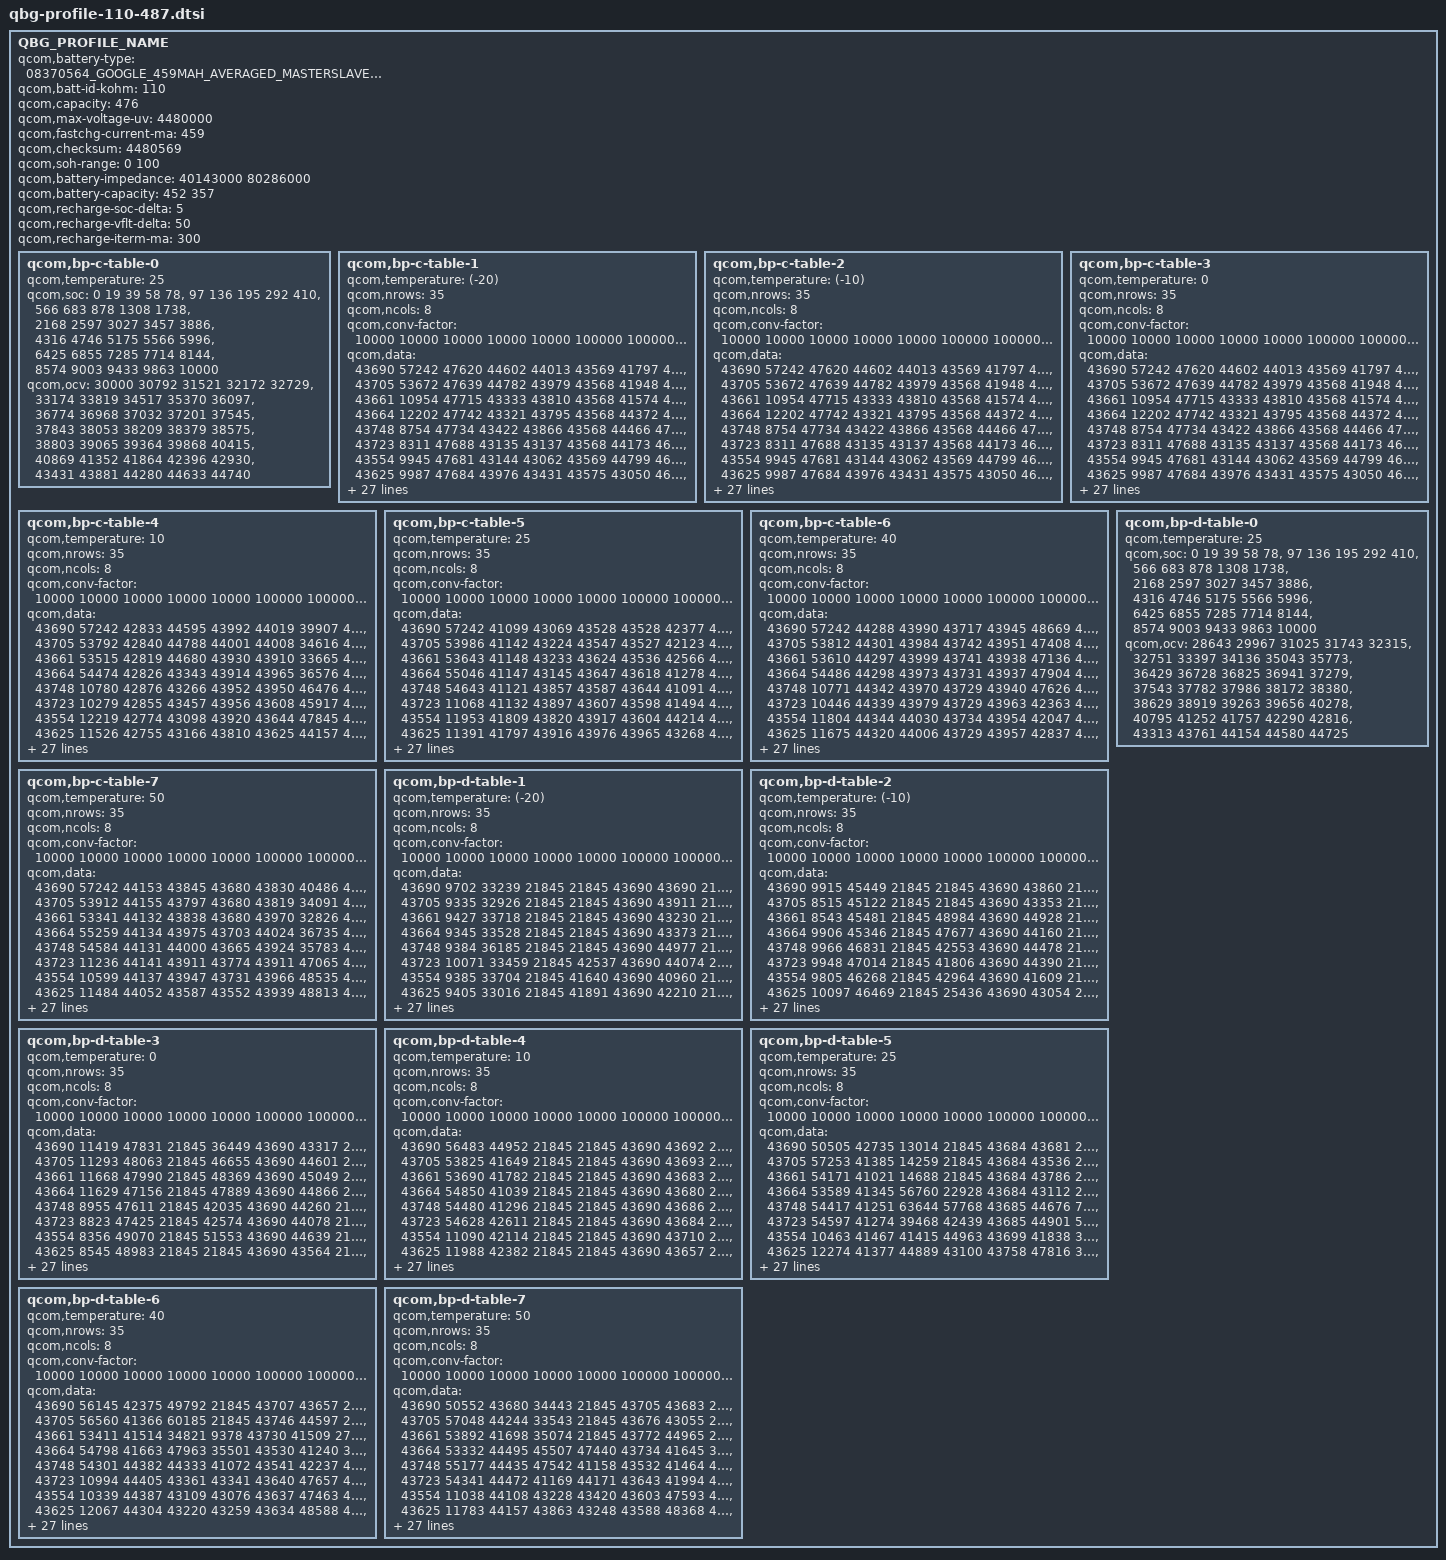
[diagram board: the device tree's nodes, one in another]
/*QBG Profiling Rev. 2.8*/

QBG_PROFILE_NAME {
	qcom,battery-type = "08370564_GOOGLE_459MAH_AVERAGED_MASTERSLAVE_MAR4TH2026";
	qcom,batt-id-kohm = <110>;
	qcom,capacity = <476>;
	qcom,max-voltage-uv = <4480000>;
	qcom,fastchg-current-ma = <459>;
	qcom,checksum = <4480569>; /*@5, 0.005V, 4% */
	qcom,soh-range = <0 100>;
	qcom,battery-impedance = <40143000 80286000>; /*Nominal_Impedance in 10nohm @ SOC 50% 25C* 0:fresh cell, 1: aged cell*/
	qcom,battery-capacity = <452 357>; /*Nominal_Capacity in mAh. 0: fresh cell, 1:aged cell*/ 
	qcom,recharge-soc-delta =<5>; /*SOC delta (in percent) dropped from EOC SOC to enable recharge*/ 
	qcom,recharge-vflt-delta =<50>; /*vfloat delta (in mV) dropped from regular vfloat in recharge*/ 
	qcom,recharge-iterm-ma = <300>; /*termination current (in mA) in recharge*/ 

	qcom,bp-c-table-0 {
		qcom,temperature = <25>;
		qcom,soc = <    0    19    39    58    78>,
			<   97   136   195   292   410>,
			<  566   683   878  1308  1738>,
			< 2168  2597  3027  3457  3886>,
			< 4316  4746  5175  5566  5996>,
			< 6425  6855  7285  7714  8144>,
			< 8574  9003  9433  9863 10000>;
		qcom,ocv = <30000 30792 31521 32172 32729>,
			<33174 33819 34517 35370 36097>,
			<36774 36968 37032 37201 37545>,
			<37843 38053 38209 38379 38575>,
			<38803 39065 39364 39868 40415>,
			<40869 41352 41864 42396 42930>,
			<43431 43881 44280 44633 44740>;
	};
	qcom,bp-c-table-1 {
		qcom,temperature = <(-20)>;
		qcom,nrows = <35>;
		qcom,ncols = <8>;
		qcom,conv-factor = <10000 10000 10000 10000 10000 100000 100000 10000>;
		qcom,data = <43690 57242 47620 44602 44013 43569 41797 46970>,
			<43705 53672 47639 44782 43979 43568 41948 46856>,
			<43661 10954 47715 43333 43810 43568 41574 47070>,
			<43664 12202 47742 43321 43795 43568 44372 47085>,
			<43748  8754 47734 43422 43866 43568 44466 47024>,
			<43723  8311 47688 43135 43137 43568 44173 46661>,
			<43554  9945 47681 43144 43062 43569 44799 46645>,
			<43625  9987 47684 43976 43431 43575 43050 46743>,
			<43918  9670 47718 43602 43405 43534 43862 45436>,
			<43824 15100 47735 43734 43307 43531 43808 45351>,
			<43164 14854 47725 43529 43495 43532 43798 45564>,
			<43009 14967 47725 43533 43515 43526 43874 45561>,
			<43460 15249 47712 43638 43416 43538 43171 45512>,
			<44982 14381 48039 43977 44565 43522 43837 47076>,
			<44128 14594 48124 44874 43104 43551 48741 46437>,
			<41682 16087 48055 41688 43985 43537 46532 35346>,
			<41103 16293 47706 41919 43891 43538 47010 35817>,
			<41337 16162 47703 41928 43188 43550 45266 35661>,
			<42795 15537 48024 41747 43255 43525 45688 34924>,
			<42372 15481 48094 41098 43047 43520 45980 35075>,
			<47734 15724 47920 41173 43068 43534 46002 36601>,
			<47136 13219 47890 41066 43058 43572 48266 36431>,
			<48797 12327 47940 41031 43025 43580 42095 36635>,
			<48916 12637 47331 41372 43403 43557 41074 35904>,
			<48582 14129 47148 41435 43371 43565 44391 33477>,
			<46003 13820 47218 41238 44753 43562 44174 32916>,
			<45165  2957 47596 42656 45054 43734 44930 34549>,
			<46815  2468 47377 42728 44226 43731 44764 33906>,
			<46216  4015 48774 42709 44408 43731 43353 39782>,
			<46458  3501 48653 42512 41748 43734 43299 40715>,
			<35796   607 49057 42884 42717 43732 43503 36901>,
			<35201    17 49098 42583 48104 43733 43083 60256>,
			<36467  1735 48998 41174 48128 43521 43173 60443>,
			<35885  1857 48190 44844 45613 43647 43967 60762>,
			<36282  1260 48524 44644 48539 43768 43585 58042>;
	};
	qcom,bp-c-table-2 {
		qcom,temperature = <(-10)>;
		qcom,nrows = <35>;
		qcom,ncols = <8>;
		qcom,conv-factor = <10000 10000 10000 10000 10000 100000 100000 10000>;
		qcom,data = <43690 57242 47620 44602 44013 43569 41797 46970>,
			<43705 53672 47639 44782 43979 43568 41948 46856>,
			<43661 10954 47715 43333 43810 43568 41574 47070>,
			<43664 12202 47742 43321 43795 43568 44372 47085>,
			<43748  8754 47734 43422 43866 43568 44466 47024>,
			<43723  8311 47688 43135 43137 43568 44173 46661>,
			<43554  9945 47681 43144 43062 43569 44799 46645>,
			<43625  9987 47684 43976 43431 43575 43050 46743>,
			<43918  9670 47718 43602 43405 43534 43862 45436>,
			<43824 15100 47735 43734 43307 43531 43808 45351>,
			<43164 14854 47725 43529 43495 43532 43798 45564>,
			<43009 14967 47725 43533 43515 43526 43874 45561>,
			<43460 15249 47712 43638 43416 43538 43171 45512>,
			<44982 14381 48039 43977 44565 43522 43837 47076>,
			<44128 14594 48124 44874 43104 43551 48741 46437>,
			<41682 16087 48055 41688 43985 43537 46532 35346>,
			<41103 16293 47706 41919 43891 43538 47010 35817>,
			<41337 16162 47703 41928 43188 43550 45266 35661>,
			<42795 15537 48024 41747 43255 43525 45688 34924>,
			<42372 15481 48094 41098 43047 43520 45980 35075>,
			<47734 15724 47920 41173 43068 43534 46002 36601>,
			<47136 13219 47890 41066 43058 43572 48266 36431>,
			<48797 12327 47940 41031 43025 43580 42095 36635>,
			<48916 12637 47331 41372 43403 43557 41074 35904>,
			<48582 14129 47148 41435 43371 43565 44391 33477>,
			<46003 13820 47218 41238 44753 43562 44174 32916>,
			<45165  2957 47596 42656 45054 43734 44930 34549>,
			<46815  2468 47377 42728 44226 43731 44764 33906>,
			<46216  4015 48774 42709 44408 43731 43353 39782>,
			<46458  3501 48653 42512 41748 43734 43299 40715>,
			<35796   607 49057 42884 42717 43732 43503 36901>,
			<35201    17 49098 42583 48104 43733 43083 60256>,
			<36467  1735 48998 41174 48128 43521 43173 60443>,
			<35885  1857 48190 44844 45613 43647 43967 60762>,
			<36282  1260 48524 44644 48539 43768 43585 58042>;
	};
	qcom,bp-c-table-3 {
		qcom,temperature = <0>;
		qcom,nrows = <35>;
		qcom,ncols = <8>;
		qcom,conv-factor = <10000 10000 10000 10000 10000 100000 100000 10000>;
		qcom,data = <43690 57242 47620 44602 44013 43569 41797 46970>,
			<43705 53672 47639 44782 43979 43568 41948 46856>,
			<43661 10954 47715 43333 43810 43568 41574 47070>,
			<43664 12202 47742 43321 43795 43568 44372 47085>,
			<43748  8754 47734 43422 43866 43568 44466 47024>,
			<43723  8311 47688 43135 43137 43568 44173 46661>,
			<43554  9945 47681 43144 43062 43569 44799 46645>,
			<43625  9987 47684 43976 43431 43575 43050 46743>,
			<43918  9670 47718 43602 43405 43534 43862 45436>,
			<43824 15100 47735 43734 43307 43531 43808 45351>,
			<43164 14854 47725 43529 43495 43532 43798 45564>,
			<43009 14967 47725 43533 43515 43526 43874 45561>,
			<43460 15249 47712 43638 43416 43538 43171 45512>,
			<44982 14381 48039 43977 44565 43522 43837 47076>,
			<44128 14594 48124 44874 43104 43551 48741 46437>,
			<41682 16087 48055 41688 43985 43537 46532 35346>,
			<41103 16293 47706 41919 43891 43538 47010 35817>,
			<41337 16162 47703 41928 43188 43550 45266 35661>,
			<42795 15537 48024 41747 43255 43525 45688 34924>,
			<42372 15481 48094 41098 43047 43520 45980 35075>,
			<47734 15724 47920 41173 43068 43534 46002 36601>,
			<47136 13219 47890 41066 43058 43572 48266 36431>,
			<48797 12327 47940 41031 43025 43580 42095 36635>,
			<48916 12637 47331 41372 43403 43557 41074 35904>,
			<48582 14129 47148 41435 43371 43565 44391 33477>,
			<46003 13820 47218 41238 44753 43562 44174 32916>,
			<45165  2957 47596 42656 45054 43734 44930 34549>,
			<46815  2468 47377 42728 44226 43731 44764 33906>,
			<46216  4015 48774 42709 44408 43731 43353 39782>,
			<46458  3501 48653 42512 41748 43734 43299 40715>,
			<35796   607 49057 42884 42717 43732 43503 36901>,
			<35201    17 49098 42583 48104 43733 43083 60256>,
			<36467  1735 48998 41174 48128 43521 43173 60443>,
			<35885  1857 48190 44844 45613 43647 43967 60762>,
			<36282  1260 48524 44644 48539 43768 43585 58042>;
	};
	qcom,bp-c-table-4 {
		qcom,temperature = <10>;
		qcom,nrows = <35>;
		qcom,ncols = <8>;
		qcom,conv-factor = <10000 10000 10000 10000 10000 100000 100000 10000>;
		qcom,data = <43690 57242 42833 44595 43992 44019 39907 45741>,
			<43705 53792 42840 44788 44001 44008 34616 48415>,
			<43661 53515 42819 44680 43930 43910 33665 48586>,
			<43664 54474 42826 43343 43914 43965 36576 48544>,
			<43748 10780 42876 43266 43952 43950 46476 48156>,
			<43723 10279 42855 43457 43956 43608 45917 48329>,
			<43554 12219 42774 43098 43920 43644 47845 48998>,
			<43625 11526 42755 43166 43810 43625 44157 49035>,
			<43918  8256 42800 43588 43216 43636 43165 48676>,
			<43824  9987 42803 43624 43221 43602 43173 48775>,
			<43164 15026 42961 43722 43020 43958 43784 47469>,
			<43009 14907 42787 43721 43008 43956 43826 47370>,
			<43460 14969 42957 43531 43207 43955 43179 47397>,
			<44982 15112 42947 44697 43647 43595 45463 49103>,
			<44128 14431 42986 44933 43948 43616 35571 48261>,
			<41682 16038 42916 44812 43910 43631 46547 48373>,
			<41103 15994 42568 44913 44003 43625 45349 48320>,
			<41337 16370 42604 44864 43975 43624 45782 48345>,
			<42795 16197 42526 44889 43835 43624 48263 48173>,
			<42372 15369 42520 44216 43776 43624 48404 48135>,
			<47734 15657 42544 44185 43781 43624 46619 48226>,
			<47136 12833 42551 44045 43803 43541 32906 48609>,
			<48797 12444 42523 44050 43828 43549 46396 48625>,
			<48916 12633 42592 44136 43788 43527 48101 48426>,
			<48582 14102 42562 44114 43860 43534 41454 45806>,
			<46003 13612 42937 44521 43206 43569 41506 46063>,
			<45165  3023 42983 44314 43135 43576 44530 45266>,
			<46815  2550 42808 41603 43491 43559 44131 45435>,
			<46216  4033 42865 41671 43356 43553 44888 47099>,
			<46458  3537 42115 41497 44633 43553 45054 46483>,
			<35796   986 42200 41500 44069 43556 44558 35589>,
			<35201   413 42001 41504 41939 43582 43331 36823>,
			<36467  1662 42424 44289 42780 43581 43431 33626>,
			<35885  1173 42253 44651 42108 43565 43880 32963>,
			<36282  1085 47774 43338 42701 43737 44018 33408>;
	};
	qcom,bp-c-table-5 {
		qcom,temperature = <25>;
		qcom,nrows = <35>;
		qcom,ncols = <8>;
		qcom,conv-factor = <10000 10000 10000 10000 10000 100000 100000 10000>;
		qcom,data = <43690 57242 41099 43069 43528 43528 42377 42066>,
			<43705 53986 41142 43224 43547 43527 42123 42098>,
			<43661 53643 41148 43233 43624 43536 42566 42013>,
			<43664 55046 41147 43145 43647 43618 41278 42045>,
			<43748 54643 41121 43857 43587 43644 41091 42194>,
			<43723 11068 41132 43897 43607 43598 41494 42224>,
			<43554 11953 41809 43820 43917 43604 44214 42121>,
			<43625 11391 41797 43916 43976 43965 43268 42827>,
			<43918  8320 41803 43527 43796 43918 43051 42800>,
			<43824 10155 41848 43565 43898 43945 43166 42954>,
			<43164  9484 41748 43920 43600 43935 44872 42889>,
			<43009 15042 41755 43646 44026 43912 43518 42583>,
			<43460 14850 41755 43535 43813 43909 43078 42583>,
			<44982 15355 41781 43106 43646 43592 48774 42178>,
			<44128 14339 41768 43411 43939 43641 48748 42054>,
			<41682 14713 41975 43475 43960 43623 48975 42414>,
			<41103 15887 41877 43320 43960 43622 48354 42411>,
			<41337 16363 41859 43300 43904 43623 47534 42077>,
			<42795 16193 41915 43475 43977 43621 42837 42410>,
			<42372 15365 41903 43457 43788 43621 41301 42369>,
			<47734 15673 41565 43310 43885 43617 42161 42480>,
			<47136 12851 41541 43370 43886 43622 48672 42298>,
			<48797 13166 41540 44680 43830 43644 33956 42261>,
			<48916 12566 41539 43375 43978 43643 46015 42368>,
			<48582 14197 41550 43299 44017 43616 41855 42060>,
			<46003 13583 41550 43289 43808 43624 41620 42478>,
			<45165  2850 41541 44727 43891 43544 44145 47804>,
			<46815  2338 41897 44765 43163 43520 44223 47692>,
			<46216  3894 41870 44663 43218 43532 44186 47978>,
			<46458  3352 41979 44970 43454 43532 45012 47111>,
			<35796   781 41947 44975 43332 43526 44624 47465>,
			<35201   451 41780 44630 45037 43549 44596 49143>,
			<36467  1618 41849 44576 41715 43627 43360 45795>,
			<35885  1267 41186 43400 41486 43527 43104 45731>,
			<36282  1134 41050 43173 44499 43626 43821 48141>;
	};
	qcom,bp-c-table-6 {
		qcom,temperature = <40>;
		qcom,nrows = <35>;
		qcom,ncols = <8>;
		qcom,conv-factor = <10000 10000 10000 10000 10000 100000 100000 10000>;
		qcom,data = <43690 57242 44288 43990 43717 43945 48669 41104>,
			<43705 53812 44301 43984 43742 43951 47408 41118>,
			<43661 53610 44297 43999 43741 43938 47136 41095>,
			<43664 54486 44298 43973 43731 43937 47904 41103>,
			<43748 10771 44342 43970 43729 43940 47626 41142>,
			<43723 10446 44339 43979 43729 43963 42363 41145>,
			<43554 11804 44344 44030 43734 43954 42047 41131>,
			<43625 11675 44320 44006 43729 43957 42837 41799>,
			<43918  8441 44331 44000 43741 43907 42004 41842>,
			<43824 10145 44509 43918 43579 43927 41116 41748>,
			<43164  9533 44506 43592 43548 43980 44427 41786>,
			<43009 15094 44483 43962 43727 44011 47226 41926>,
			<43460 14904 44494 43960 43728 44009 47813 41943>,
			<44982 15259 44534 43815 43604 43938 41357 40993>,
			<44128 14382 44516 43880 43952 43604 41298 41078>,
			<41682 14592 44437 43847 43938 43615 47903 41033>,
			<41103 15919 44421 43867 43602 43611 47142 41060>,
			<41337 16272 44426 43844 43607 43608 42003 41071>,
			<42795 16208 44472 43895 43926 43612 41127 41036>,
			<42372 15458 44460 43815 43903 43601 44196 41356>,
			<47734 15623 44117 43801 43866 43590 41658 41417>,
			<47136 12819 44113 43858 43890 43596 42715 41253>,
			<48797 13144 44125 43210 43834 43605 46686 41216>,
			<48916 12632 44127 43860 44012 43608 42146 41387>,
			<48582 14163 44121 43884 44001 43586 44275 41081>,
			<46003 13678 44126 43877 43999 43595 44949 41389>,
			<45165  2822 44114 43865 43788 43644 44593 41412>,
			<46815  2331 44116 43164 43894 43618 44745 41296>,
			<46216  3950 44462 43106 43184 43536 44563 42570>,
			<46458  3454 44478 43092 43217 43539 44561 42793>,
			<35796   789 44429 43507 43130 43621 44861 42217>,
			<35201   466 44522 43468 43320 43598 44814 42374>,
			<36467  1962 44483 43436 45018 43589 44583 47618>,
			<35885  1271 44311 43144 44842 43638 43330 47765>,
			<36282  1150 41511 43875 44998 43963 43165 47669>;
	};
	qcom,bp-c-table-7 {
		qcom,temperature = <50>;
		qcom,nrows = <35>;
		qcom,ncols = <8>;
		qcom,conv-factor = <10000 10000 10000 10000 10000 100000 100000 10000>;
		qcom,data = <43690 57242 44153 43845 43680 43830 40486 41548>,
			<43705 53912 44155 43797 43680 43819 34091 41545>,
			<43661 53341 44132 43838 43680 43970 32826 41589>,
			<43664 55259 44134 43975 43703 44024 36735 41584>,
			<43748 54584 44131 44000 43665 43924 35783 41599>,
			<43723 11236 44141 43911 43774 43911 47065 41594>,
			<43554 10599 44137 43947 43731 43966 48535 41583>,
			<43625 11484 44052 43587 43552 43939 48813 41494>,
			<43918  8978 44050 43958 43773 43930 45649 41502>,
			<43824  9763 44059 43609 43740 44000 42794 41524>,
			<43164  9604 44033 43628 43581 43984 44405 41513>,
			<43009 14987 44034 43524 43718 43817 42971 41623>,
			<43460 15095 44047 43641 43712 43971 47247 41674>,
			<44982 14938 44043 43914 43603 43922 41954 41952>,
			<44128 14562 44082 44011 43960 43910 41740 41763>,
			<41682 14787 44069 44021 43942 43913 42394 41784>,
			<41103 16127 44078 44017 43600 43957 42276 41949>,
			<41337 16270 44242 44021 43586 43953 42956 41928>,
			<42795 16199 44228 44020 43940 43956 40971 41762>,
			<42372 15465 44239 43612 43884 43920 44560 41826>,
			<47734 15620 44234 43960 43848 43953 44244 41815>,
			<47136 12907 44278 44020 43798 43940 41348 41098>,
			<48797 12462 44272 43804 43986 43941 45976 41114>,
			<48916 13996 44275 43970 43967 43960 41290 41771>,
			<48582 14165 44274 43931 43956 43961 44802 41930>,
			<46003 13669 44274 43926 44015 43936 44654 41765>,
			<45165  2834 44273 43998 44019 43615 44670 41817>,
			<46815  2410 44277 43882 43989 43636 44646 41181>,
			<46216  3965 44233 43190 43883 43621 44569 41358>,
			<46458  3403 44225 43051 43843 43622 44902 41322>,
			<35796   865 44243 43071 43212 43633 44827 42748>,
			<35201   297 44076 43069 43431 43614 44846 42924>,
			<36467  1962 44043 43207 44772 43966 44950 42120>,
			<35885  1225 44145 43988 44688 43606 43388 43000>,
			<36282  1136 44308 43884 43382 43930 43454 42174>;
	};
	qcom,bp-d-table-0 {
		qcom,temperature = <25>;
		qcom,soc = <    0    19    39    58    78>,
			<   97   136   195   292   410>,
			<  566   683   878  1308  1738>,
			< 2168  2597  3027  3457  3886>,
			< 4316  4746  5175  5566  5996>,
			< 6425  6855  7285  7714  8144>,
			< 8574  9003  9433  9863 10000>;
		qcom,ocv = <28643 29967 31025 31743 32315>,
			<32751 33397 34136 35043 35773>,
			<36429 36728 36825 36941 37279>,
			<37543 37782 37986 38172 38380>,
			<38629 38919 39263 39656 40278>,
			<40795 41252 41757 42290 42816>,
			<43313 43761 44154 44580 44725>;
	};
	qcom,bp-d-table-1 {
		qcom,temperature = <(-20)>;
		qcom,nrows = <35>;
		qcom,ncols = <8>;
		qcom,conv-factor = <10000 10000 10000 10000 10000 100000 100000 10000>;
		qcom,data = <43690  9702 33239 21845 21845 43690 43690 21845>,
			<43705  9335 32926 21845 21845 43690 43911 21845>,
			<43661  9427 33718 21845 21845 43690 43230 21845>,
			<43664  9345 33528 21845 21845 43690 43373 21845>,
			<43748  9384 36185 21845 21845 43690 44977 21845>,
			<43723 10071 33459 21845 42537 43690 44074 21845>,
			<43554  9385 33704 21845 41640 43690 40960 21845>,
			<43625  9405 33016 21845 41891 43690 42210 21845>,
			<43918  9294 33277 21845 18957 43690 43736 21845>,
			<43824  9607 32872 21845 56997 43690 43535 21845>,
			<43164  9513 32805 21845 60280 43690 43618 21845>,
			<43009  9568 33597 21845 34815 43690 43936 21845>,
			<43460 15001 36159 21845 36554 43690 43825 21845>,
			<44982 15272 36471 15036 45174 43691 43023 21845>,
			<44128 15108 35039 65214 47377 43688 43471 23503>,
			<41682 14584 35774 36921 41986 43689 44782  4417>,
			<41103 14425 46353 33035 41414 43694 44643 12313>,
			<41337 14640 46197 35054 41777 43695 44627 12182>,
			<42795 16121 46284 46784 41685 43692 44991 56442>,
			<42372 16305 46886 45606 44327 43693 44998 50830>,
			<47734 16208 46917 48290 44140 43683 44200 53135>,
			<47136 15445 47068 49083 44180 43680 44126 51416>,
			<48797 13029 47061 48754 44179 43680 41492 52186>,
			<48916 13079 46886 48649 44229 43681 41097 52118>,
			<48582 12757 47042 48867 44430 43686 41036 52206>,
			<46003 14299 46886 48878 44376 43687 41438 51973>,
			<45165 13790 46212 48698 41593 43684 41400 51224>,
			<46815  2849 46908 48680 41950 43707 41352 51677>,
			<46216  2368 47040 48819 41926 43750 42053 53181>,
			<46458  3224 47090 48827 41948 43740 48069 52340>,
			<35796   694 47034 48710 41748 43719 42395 52537>,
			<35201   886 46661 48930 41931 43722 41427 52515>,
			<36467   284 47036 48403 41619 43700 44366 52299>,
			<35885  1884 46890 45073 44047 43690 44779 53014>,
			<36282  1134 46852 45346 44182 43690 43452 53244>;
	};
	qcom,bp-d-table-2 {
		qcom,temperature = <(-10)>;
		qcom,nrows = <35>;
		qcom,ncols = <8>;
		qcom,conv-factor = <10000 10000 10000 10000 10000 100000 100000 10000>;
		qcom,data = <43690  9915 45449 21845 21845 43690 43860 21845>,
			<43705  8515 45122 21845 21845 43690 43353 21845>,
			<43661  8543 45481 21845 48984 43690 44928 21845>,
			<43664  9906 45346 21845 47677 43690 44160 21845>,
			<43748  9966 46831 21845 42553 43690 44478 21845>,
			<43723  9948 47014 21845 41806 43690 44390 21845>,
			<43554  9805 46268 21845 42964 43690 41609 21845>,
			<43625 10097 46469 21845 25436 43690 43054 21845>,
			<43918  9218 46582 21845  7142 43690 43565 21845>,
			<43824  9653 46158 21845 60053 43690 43585 21845>,
			<43164  9521 46319 21845 45365 43690 43998 21845>,
			<43009  9554 46659 16741 47917 43690 43138 21845>,
			<43460 15058 46754 63012 41010 43691 43488 21165>,
			<44982 15252 45591 35863 41892 43689 44667  9586>,
			<44128 15220 48549 48466 44225 43695 44883 52393>,
			<41682 14547 48232 47109 44850 43693 44223 64612>,
			<41103 14783 48205 42363 45040 43680 44804 64130>,
			<41337 14614 48564 42848 44979 43687 44835 57809>,
			<42795 16081 48572 42621 44785 43707 44438 58109>,
			<42372 16324 48521 42647 44710 43699 41741 60453>,
			<47734 15369 48532 41353 43372 43716 47799 61205>,
			<47136 15702 48622 41378 44713 43552 48024 61205>,
			<48797 13274 48616 41455 44589 43556 47649 61284>,
			<48916 12364 48532 41271 44609 43578 42254 61305>,
			<48582 13853 48540 42650 45004 43579 42446 60594>,
			<46003 13342 46010 42568 44888 43556 42049 60487>,
			<45165  2659 48605 42774 44227 43554 42016 60751>,
			<46815  2117 48531 41994 44148 43563 42238 58294>,
			<46216  4027 48528 42494 44515 43731 42774 57506>,
			<46458  3507 48515 42308 44350 43736 42544 57417>,
			<35796   606 48545 47658 44292 43713 41463 57727>,
			<35201    60 48518 47715 44513 43721 41785 59061>,
			<36467  1677 48207 47676 44814 43772 41472 57756>,
			<35885  1203 48353 42334 43492 43756 41497 58157>,
			<36282  1124 48314 42252 43115 43755 41900 58277>;
	};
	qcom,bp-d-table-3 {
		qcom,temperature = <0>;
		qcom,nrows = <35>;
		qcom,ncols = <8>;
		qcom,conv-factor = <10000 10000 10000 10000 10000 100000 100000 10000>;
		qcom,data = <43690 11419 47831 21845 36449 43690 43317 21845>,
			<43705 11293 48063 21845 46655 43690 44601 21845>,
			<43661 11668 47990 21845 48369 43690 45049 21845>,
			<43664 11629 47156 21845 47889 43690 44866 21845>,
			<43748  8955 47611 21845 42035 43690 44260 21845>,
			<43723  8823 47425 21845 42574 43690 44078 21845>,
			<43554  8356 49070 21845 51553 43690 44639 21845>,
			<43625  8545 48983 21845 21845 43690 43564 21845>,
			<43918 10199 48184 21845 13531 43690 43717 21845>,
			<43824  9265 49013 21845 34140 43690 43604 21845>,
			<43164  9711 48727 19819 42024 43690 43141 21845>,
			<43009  9535 48698 51378 44294 43691 43518 16696>,
			<43460 15033 47368 46766 44968 43688 44753 54653>,
			<44982 14942 47345 42996 43323 43693 44469 57356>,
			<44128 15123 47259 41765 43078 43658 41002 36878>,
			<41682 14385 47266 41632 43050 43555 48921 40485>,
			<41103 14845 47353 44305 43061 43580 48134 39846>,
			<41337 14677 47349 44507 43060 43569 47188 33794>,
			<42795 15990 47322 44486 43107 43530 47537 34595>,
			<42372 16229 47320 44533 43436 43528 47695 34403>,
			<47734 15434 47350 44482 43423 43535 41994 34559>,
			<47136 12979 47304 44348 43511 43532 42969 34486>,
			<48797 13098 47147 44406 43322 43534 42496 34469>,
			<48916 12381 47345 41618 43364 43531 42736 34542>,
			<48582 13926 47333 41496 44724 43575 42642 34315>,
			<46003 13437 47305 41983 44756 43570 42536 34599>,
			<45165  2644 47333 41818 44661 43576 42688 33828>,
			<46815  2433 47353 41159 44957 43558 41321 34059>,
			<46216  4064 47358 40991 45012 43567 41166 39623>,
			<46458  3556 47256 41084 44848 43733 41893 39499>,
			<35796   902 47240 41030 44845 43728 41684 39815>,
			<35201   115 47295 41384 44965 43730 41497 39918>,
			<36467  1776 47245 41022 44735 43737 41551 39542>,
			<35885  1167 47355 41841 43036 43719 41917 39558>,
			<36282  1123 47307 41759 43234 43713 41869 39596>;
	};
	qcom,bp-d-table-4 {
		qcom,temperature = <10>;
		qcom,nrows = <35>;
		qcom,ncols = <8>;
		qcom,conv-factor = <10000 10000 10000 10000 10000 100000 100000 10000>;
		qcom,data = <43690 56483 44952 21845 21845 43690 43692 21845>,
			<43705 53825 41649 21845 21845 43690 43693 21845>,
			<43661 53690 41782 21845 21845 43690 43683 21845>,
			<43664 54850 41039 21845 21845 43690 43680 21845>,
			<43748 54480 41296 21845 21845 43690 43686 21845>,
			<43723 54628 42611 21845 21845 43690 43684 21845>,
			<43554 11090 42114 21845 21845 43690 43710 21845>,
			<43625 11988 42382 21845 21845 43690 43657 21845>,
			<43918 11597 47771 21845 21845 43690 43762 21845>,
			<43824  8274 47803 21845 34111 43690 43605 21845>,
			<43164  9387 42461 53331 41884 43691 43518 22374>,
			<43009  9654 42429 33186 44627 43691 44821 15343>,
			<43460  9481 42047 41718 43119 43683 44325 38832>,
			<44982 15084 42003 44763 43821 43716 41197 34845>,
			<44128 15152 42211 45013 43188 43575 49123 35419>,
			<41682 14395 42122 45029 43011 43527 47273 46293>,
			<41103 14840 42144 45025 43008 43548 47345 47027>,
			<41337 16033 42838 45032 43020 43536 47961 46739>,
			<42795 15996 42837 44959 43010 43537 47789 45362>,
			<42372 16147 42158 44954 43022 43537 42877 45489>,
			<47734 15383 42832 44950 43066 43536 42527 45152>,
			<47136 15681 42123 45041 43053 43538 42703 45060>,
			<48797 13293 42155 44997 43061 43551 41408 45074>,
			<48916 12305 42144 44855 43113 43550 41278 45149>,
			<48582 13873 42158 44888 43438 43544 42643 45358>,
			<46003 13434 42155 44089 43463 43545 42433 46650>,
			<45165  3006 42834 44456 43385 43547 42310 46909>,
			<46815  2460 42842 44455 44735 43533 42671 46210>,
			<46216  4064 42839 44112 44672 43530 41910 46114>,
			<46458  3574 42137 44469 44707 43575 41514 46511>,
			<35796  1005 42153 44435 43387 43568 41482 46377>,
			<35201    84 42168 44421 43319 43570 41881 46460>,
			<36467  1750 42120 44110 43446 43583 41939 46436>,
			<35885  1159 42140 44238 43211 43579 41973 46390>,
			<36282  1134 42131 44266 43143 43578 41899 46548>;
	};
	qcom,bp-d-table-5 {
		qcom,temperature = <25>;
		qcom,nrows = <35>;
		qcom,ncols = <8>;
		qcom,conv-factor = <10000 10000 10000 10000 10000 100000 100000 10000>;
		qcom,data = <43690 50505 42735 13014 21845 43684 43681 21845>,
			<43705 57253 41385 14259 21845 43684 43536 21845>,
			<43661 54171 41021 14688 21845 43684 43786 21845>,
			<43664 53589 41345 56760 22928 43684 43112 21845>,
			<43748 54417 41251 63644 57768 43685 44676  7543>,
			<43723 54597 41274 39468 42439 43685 44901 52134>,
			<43554 10463 41467 41415 44963 43699 41838 37871>,
			<43625 12274 41377 44889 43100 43758 47816 34923>,
			<43918  8777 41063 44799 43227 43578 45794 45823>,
			<43824  8471 40960 43335 43141 43524 46282 49072>,
			<43164  9447 41187 43393 43990 43524 41378 47946>,
			<43009  9682 41116 43515 43825 43619 41070 47873>,
			<43460  9587 41103 43072 43909 43540 41290 47867>,
			<44982 15079 41817 43207 43640 43620 42386 42061>,
			<44128 15157 41753 43121 43789 43642 42690 42259>,
			<41682 14349 41765 43085 43186 43639 42713 42310>,
			<41103 14652 41775 43454 43218 43590 42415 47864>,
			<41337 16072 41942 43402 43066 43589 42376 47857>,
			<42795 16310 41922 43094 43054 43586 41323 47787>,
			<42372 16198 41981 43074 43240 43595 41089 42277>,
			<47734 15439 41953 43076 43871 43637 41109 42386>,
			<47136 12973 41966 43091 43798 43639 41026 42068>,
			<48797 13301 41877 43094 43806 43632 41395 42072>,
			<48916 12354 41875 43411 43855 43636 42160 42481>,
			<48582 14332 41862 43385 43415 43586 48608 48123>,
			<46003 13809 41869 43378 43307 43595 47587 47920>,
			<45165  2958 41869 43324 43495 43643 40997 48000>,
			<46815  2487 41859 43311 43436 43620 41715 47728>,
			<46216  3992 41883 43289 43040 43646 41672 47631>,
			<46458  3562 41966 43384 43198 43646 41915 47834>,
			<35796   923 41976 43337 43807 43643 41399 47849>,
			<35201    91 41924 43291 43787 43621 41265 47750>,
			<36467  1744 41761 43474 43785 43642 41275 47770>,
			<35885  1166 41741 43421 43803 43647 41346 47852>,
			<36282  1055 41754 43402 43794 43634 41049 47867>;
	};
	qcom,bp-d-table-6 {
		qcom,temperature = <40>;
		qcom,nrows = <35>;
		qcom,ncols = <8>;
		qcom,conv-factor = <10000 10000 10000 10000 10000 100000 100000 10000>;
		qcom,data = <43690 56145 42375 49792 21845 43707 43657 21845>,
			<43705 56560 41366 60185 21845 43746 44597 21845>,
			<43661 53411 41514 34821  9378 43730 41509 27151>,
			<43664 54798 41663 47963 35501 43530 41240 38116>,
			<43748 54301 44382 44333 41072 43541 42237 46630>,
			<43723 10994 44405 43361 43341 43640 47657 47709>,
			<43554 10339 44387 43109 43076 43637 47463 42037>,
			<43625 12067 44304 43220 43259 43634 48588 42798>,
			<43918  8768 44296 43263 43190 43637 46616 42576>,
			<43824  8474 44321 43156 43236 43637 35753 42587>,
			<43164  9376 44509 43187 43605 43587 45889 41466>,
			<43009  9679 44504 43240 43955 43586 41413 41273>,
			<43460  9539 44492 43188 43591 43596 42753 41371>,
			<44982 14994 44540 44020 43533 43936 47659 41813>,
			<44128 15315 44432 43879 43928 43940 42964 41051>,
			<41682 14382 44416 43794 43828 43941 41042 41357>,
			<41103 14629 44430 43881 43155 43914 41015 41327>,
			<41337 16080 44469 43893 43219 44001 41742 42675>,
			<42795 16276 44476 43170 43154 44029 41751 42670>,
			<42372 15549 44455 43194 43843 44010 41179 41220>,
			<47734 15803 44460 43170 43825 43908 41430 41464>,
			<47136 12929 44117 43867 44025 43954 41281 41029>,
			<48797 13264 44119 43851 43927 43945 42521 41071>,
			<48916 12672 44114 43162 43794 43914 47136 41249>,
			<48582 14328 44126 43160 43092 43942 42190 42615>,
			<46003 13717 44120 43199 43410 43600 41708 42581>,
			<45165  2992 44120 43153 43105 43942 44330 42518>,
			<46815  2482 44126 43028 43845 43912 41965 42719>,
			<46216  3982 44114 43079 44023 43937 41452 42678>,
			<46458  3480 44457 43105 43917 43610 42730 41315>,
			<35796   904 44474 43226 43918 43594 41399 41430>,
			<35201    73 44464 43145 43959 43637 41416 41345>,
			<36467  1732 44419 43849 43919 43586 41380 41041>,
			<35885  1191 44438 43802 43926 43602 41114 41029>,
			<36282  1085 44520 43785 44014 43600 41845 41053>;
	};
	qcom,bp-d-table-7 {
		qcom,temperature = <50>;
		qcom,nrows = <35>;
		qcom,ncols = <8>;
		qcom,conv-factor = <10000 10000 10000 10000 10000 100000 100000 10000>;
		qcom,data = <43690 50552 43680 34443 21845 43705 43683 21845>,
			<43705 57048 44244 33543 21845 43676 43055 21845>,
			<43661 53892 41698 35074 21845 43772 44965 21845>,
			<43664 53332 44495 45507 47440 43734 41645 39084>,
			<43748 55177 44435 47542 41158 43532 41464 46101>,
			<43723 54341 44472 41169 44171 43643 41994 48846>,
			<43554 11038 44108 43228 43420 43603 47593 42966>,
			<43625 11783 44157 43863 43248 43588 48368 41301>,
			<43918  8851 44130 43875 43845 43585 45121 41366>,
			<43824  8607 44061 43794 43242 43609 46386 41422>,
			<43164  9993 44045 43780 43961 43600 35539 41127>,
			<43009  9662 44043 43888 43647 43614 47829 41812>,
			<43460  9582 44087 43850 43624 43612 47727 41798>,
			<44982 15012 44091 43614 43583 44008 47846 41486>,
			<44128 15331 44246 43980 43943 43926 42499 41772>,
			<41682 14583 44251 43979 44021 44000 41274 41832>,
			<41103 14793 44231 43970 43781 43820 41213 41126>,
			<41337 16080 44227 43874 43861 43805 41277 41063>,
			<42795 16333 44233 43844 43194 43781 42533 41391>,
			<42372 15519 44277 43796 43842 43822 41835 41010>,
			<47734 15757 44275 43879 44022 43998 41448 41143>,
			<47136 12948 44287 43832 43959 43930 41460 41738>,
			<48797 13089 44281 43974 43937 43905 42661 41935>,
			<48916 12799 44282 43879 43778 44022 47383 41153>,
			<48582 14325 44263 43777 43119 43929 41340 41420>,
			<46003 13801 44263 43876 43032 44002 41663 41431>,
			<45165  2955 44260 43214 43896 44020 41847 41453>,
			<46815  2481 44282 43062 43926 43930 41234 41048>,
			<46216  3968 44286 43231 43948 43607 42658 41021>,
			<46458  3485 44274 43241 43639 43597 41997 41108>,
			<35796   911 44277 43859 43641 43599 42438 41796>,
			<35201    79 44237 43793 43616 43602 47795 41741>,
			<36467  1735 44249 43991 43636 43943 41999 41770>,
			<35885  1196 44078 43924 43937 43918 41431 41942>,
			<36282  1063 44064 43904 43965 43910 41010 41772>;
	};
};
